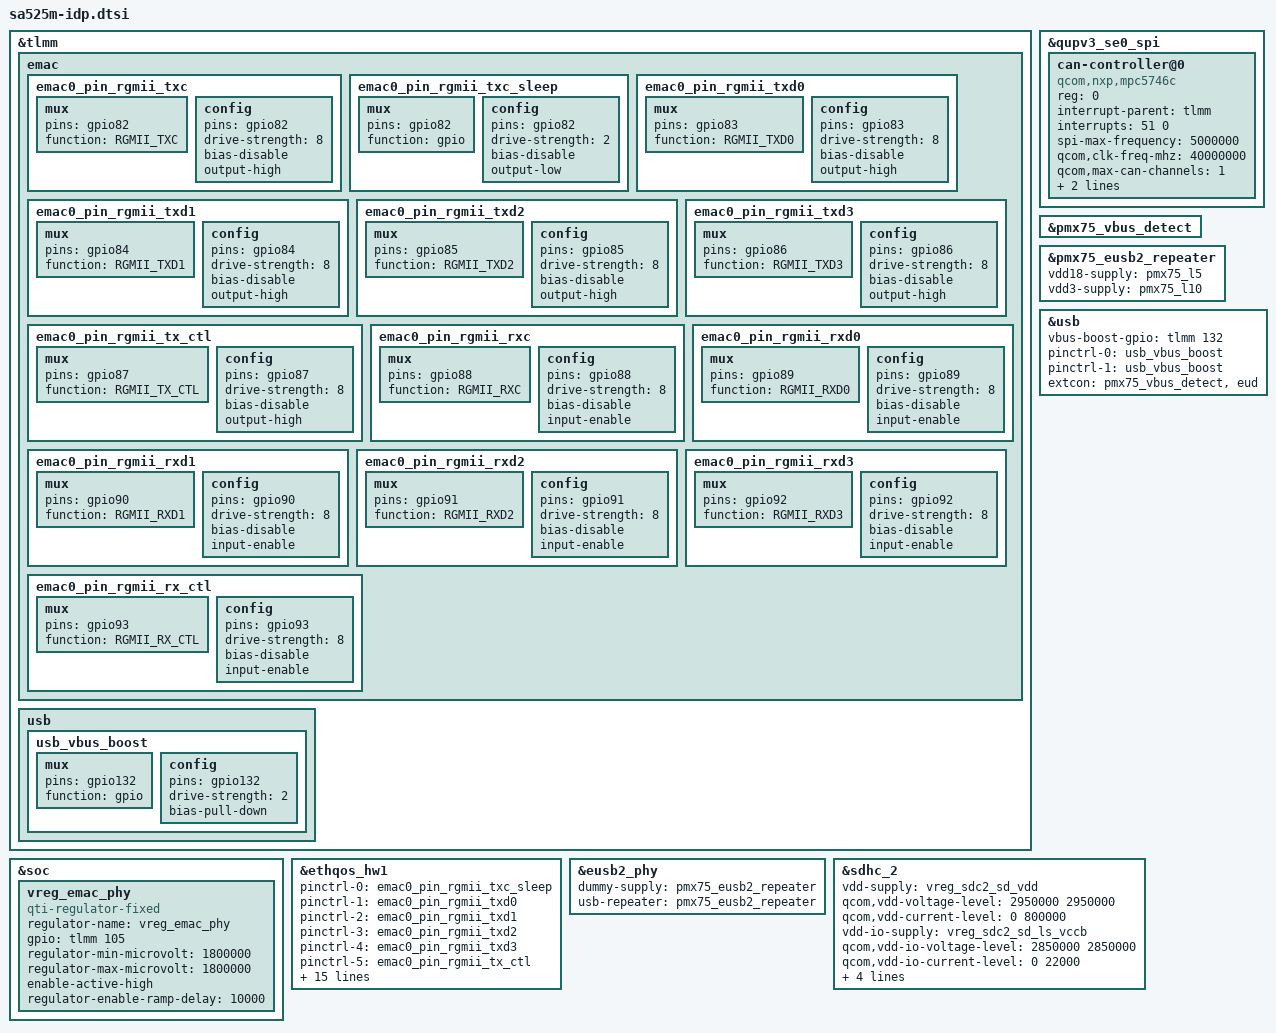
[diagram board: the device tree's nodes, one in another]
#include <dt-bindings/gpio/gpio.h>
#include <dt-bindings/clock/qcom,gcc-sdxpinn.h>

&tlmm {
	emac {
		emac0_pin_rgmii_txc: emac0_pin_rgmii_txc {
			mux {
				pins = "gpio82";
				function = "RGMII_TXC";
			};

			config {
				pins = "gpio82";
				drive-strength = <8>; /* 8 mA */
				bias-disable; /* NO PULL*/
				output-high;
			};
		};

		emac0_pin_rgmii_txc_sleep: emac0_pin_rgmii_txc_sleep {
			mux {
				pins = "gpio82";
				function = "gpio";
			};

			config {
				pins = "gpio82";
				drive-strength = <2>;
				bias-disable; /* NO PULL*/
				output-low;
			};
		};

		emac0_pin_rgmii_txd0: emac0_pin_rgmii_txd0 {
			mux {
				pins = "gpio83";
				function = "RGMII_TXD0";
			};

			config {
				pins = "gpio83";
				drive-strength = <8>; /* 8 mA */
				bias-disable; /* NO PULL*/
				output-high;
			};
		};

		emac0_pin_rgmii_txd1: emac0_pin_rgmii_txd1 {
			mux {
				pins = "gpio84";
				function = "RGMII_TXD1";
			};

			config {
				pins = "gpio84";
				drive-strength = <8>; /* 8 mA */
				bias-disable; /* NO PULL*/
				output-high;
			};
		};

		emac0_pin_rgmii_txd2: emac0_pin_rgmii_txd2 {
			mux {
				pins = "gpio85";
				function = "RGMII_TXD2";
			};

			config {
				pins = "gpio85";
				drive-strength = <8>; /* 8 mA */
				bias-disable; /* NO PULL*/
				output-high;
			};
		};

		emac0_pin_rgmii_txd3: emac0_pin_rgmii_txd3 {
			mux {
				pins = "gpio86";
				function = "RGMII_TXD3";
			};

			config {
				pins = "gpio86";
				drive-strength = <8>; /* 8 mA */
				bias-disable; /* NO PULL*/
				output-high;
			};
		};

		emac0_pin_rgmii_tx_ctl: emac0_pin_rgmii_tx_ctl {
			mux {
				pins = "gpio87";
				function = "RGMII_TX_CTL";
			};

			config {
				pins = "gpio87";
				drive-strength = <8>; /* 8 mA */
				bias-disable; /* NO PULL*/
				output-high;
			};
		};

		emac0_pin_rgmii_rxc: emac0_pin_rgmii_rxc {
			mux {
				pins = "gpio88";
				function = "RGMII_RXC";
			};

			config {
				pins = "gpio88";
				drive-strength = <8>; /* 8 mA */
				bias-disable; /* NO PULL*/
				input-enable;
			};
		};

		emac0_pin_rgmii_rxd0: emac0_pin_rgmii_rxd0 {
			mux {
				pins = "gpio89";
				function = "RGMII_RXD0";
			};

			config {
				pins = "gpio89";
				drive-strength = <8>; /* 8 mA */
				bias-disable; /* NO PULL*/
				input-enable;
			};
		};

		emac0_pin_rgmii_rxd1: emac0_pin_rgmii_rxd1 {
			mux {
				pins = "gpio90";
				function = "RGMII_RXD1";
			};

			config {
				pins = "gpio90";
				drive-strength = <8>; /* 8 mA */
				bias-disable; /* NO PULL*/
				input-enable;
			};
		};

		emac0_pin_rgmii_rxd2: emac0_pin_rgmii_rxd2 {
			mux {
				pins = "gpio91";
				function = "RGMII_RXD2";
			};

			config {
				pins = "gpio91";
				drive-strength = <8>; /* 8 mA */
				bias-disable; /* NO PULL*/
				input-enable;
			};
		};

		emac0_pin_rgmii_rxd3: emac0_pin_rgmii_rxd3 {
			mux {
				pins = "gpio92";
				function = "RGMII_RXD3";
			};

			config {
				pins = "gpio92";
				drive-strength = <8>; /* 8 mA */
				bias-disable; /* NO PULL*/
				input-enable;
			};
		};

		emac0_pin_rgmii_rx_ctl: emac0_pin_rgmii_rx_ctl {
			mux {
				pins = "gpio93";
				function = "RGMII_RX_CTL";
			};

			config {
				pins = "gpio93";
				drive-strength = <8>; /* 8 mA */
				bias-disable; /* NO PULL*/
				input-enable;
			};
		};
	};

	usb {
		usb_vbus_boost: usb_vbus_boost {
			mux {
				pins = "gpio132";
				function = "gpio";
			};

			 config {
				pins = "gpio132";
				drive-strength = <2>;
				bias-pull-down;
			};
		};
	};
};


&soc {
	vreg_emac_phy: vreg_emac_phy {
		compatible = "qti-regulator-fixed";
		regulator-name = "vreg_emac_phy";
		gpio = <&tlmm 105 GPIO_ACTIVE_HIGH>;
		regulator-min-microvolt = <1800000>;
		regulator-max-microvolt = <1800000>;
		enable-active-high;
		regulator-enable-ramp-delay = <10000>;
	};
};

&ethqos_hw1 {
		pinctrl-names = "dev-emac0_pin_rgmii_txc_sleep",
			"dev-emac0_pin_rgmii_txd0", "dev-emac0_pin_rgmii_txd1",
			"dev-emac0_pin_rgmii_txd2", "dev-emac0_pin_rgmii_txd3",
			"dev-emac0_pin_rgmii_tx_ctl", "dev-emac0_pin_rgmii_txc",
			"dev-emac0_pin_rgmii_rxc", "dev-emac0_pin_rgmii_rxd0",
			"dev-emac0_pin_rgmii_rxd1", "dev-emac0_pin_rgmii_rxd2",
			"dev-emac0_pin_rgmii_rxd3", "dev-emac0_pin_rgmii_rx_ctl",
			"dev-emac0_mdc", "dev-emac0_mdio";

		pinctrl-0 = <&emac0_pin_rgmii_txc_sleep>;
		pinctrl-1 = <&emac0_pin_rgmii_txd0>;
		pinctrl-2 = <&emac0_pin_rgmii_txd1>;
		pinctrl-3 = <&emac0_pin_rgmii_txd2>;
		pinctrl-4 = <&emac0_pin_rgmii_txd3>;
		pinctrl-5 = <&emac0_pin_rgmii_tx_ctl>;
		pinctrl-6 = <&emac0_pin_rgmii_txc>;
		pinctrl-7 = <&emac0_pin_rgmii_rxc>;
		pinctrl-8 = <&emac0_pin_rgmii_rxd0>;
		pinctrl-9 = <&emac0_pin_rgmii_rxd1>;
		pinctrl-10 = <&emac0_pin_rgmii_rxd2>;
		pinctrl-11 = <&emac0_pin_rgmii_rxd3>;
		pinctrl-12 = <&emac0_pin_rgmii_rx_ctl>;
		pinctrl-13 = <&emac0_mdc>;
		pinctrl-14 = <&emac0_mdio>;


		mac_err_rec;

		vreg_emac_phy-supply = <&vreg_emac_phy>;
		/delete-property/ snps,reset-gpio;
		snps,reset-gpio = <&tlmm 75 GPIO_ACTIVE_LOW>;
		snps,reset-delays-us = <1000 10000 1000>;

		snps,phy1_reset-gpio = <&tlmm 96 GPIO_ACTIVE_LOW>;
		snps,phy1-reset-delays-us = <1000 100000 221000>;

};

&qupv3_se0_spi {
status = "ok";

#address-cells = <1>;
#size-cells = <0>;

	can-controller@0 {
		compatible = "qcom,nxp,mpc5746c";
		reg = <0>;
		interrupt-parent = <&tlmm>;
		interrupts = <51 0>;
		spi-max-frequency = <5000000>;
		qcom,clk-freq-mhz = <40000000>;
		qcom,max-can-channels = <1>;
		qcom,bits-per-word = <8>;
		qcom,support-can-fd;
	};
};

&pmx75_vbus_detect {
	status = "ok";
};

&pmx75_eusb2_repeater {
	vdd18-supply = <&pmx75_l5>;
	vdd3-supply = <&pmx75_l10>;
	status = "ok";
};

&eusb2_phy {
	dummy-supply = <&pmx75_eusb2_repeater>;
	usb-repeater = <&pmx75_eusb2_repeater>;
};

&usb {
	vbus-boost-gpio = <&tlmm 132 GPIO_ACTIVE_HIGH>;
	pinctrl-names = "default", "sleep";
	pinctrl-0 = <&usb_vbus_boost>;
	pinctrl-1 = <&usb_vbus_boost>;
	extcon = <&pmx75_vbus_detect>, <&eud>;
};

&sdhc_2 {
	status = "ok";

	vdd-supply = <&vreg_sdc2_sd_vdd>;
	qcom,vdd-voltage-level = <2950000 2950000>;
	qcom,vdd-current-level = <0 800000>;

	vdd-io-supply = <&vreg_sdc2_sd_ls_vccb>;
	qcom,vdd-io-voltage-level = <2850000 2850000>;
	qcom,vdd-io-current-level = <0 22000>;

	pinctrl-names = "default", "sleep";
	pinctrl-0 = <&sdc2_on>;
	pinctrl-1 = <&sdc2_off>;

	cd-gpios = <&tlmm 103 GPIO_ACTIVE_LOW>;

	qcom,iommu-dma = "atomic";
};
